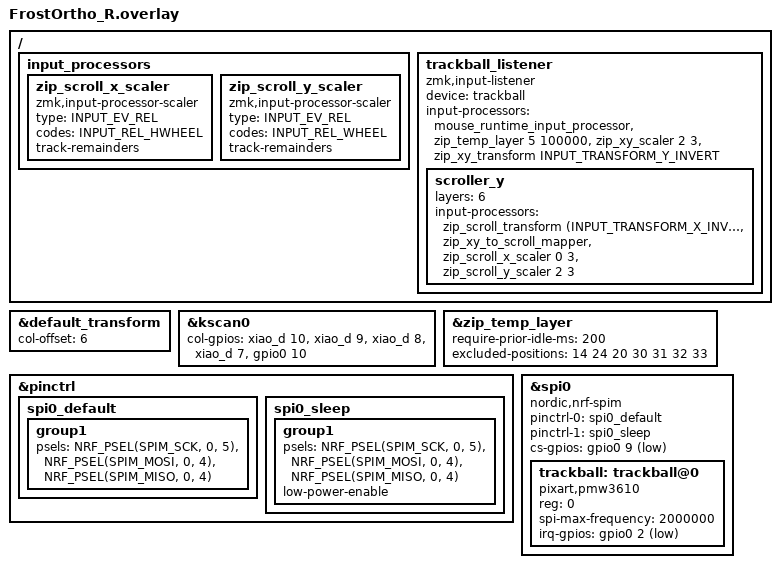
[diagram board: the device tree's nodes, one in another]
#include "FrostOrtho.dtsi"
#include <input/processors.dtsi>
#include <dt-bindings/zmk/input_transform.h>
#include <zephyr/dt-bindings/input/input-event-codes.h>
#include <input/processors/runtime-input-processor.dtsi>
#include <behaviors/battery_history_request.dtsi>

&default_transform {
    col-offset = <6>;
};

&kscan0 {
    col-gpios
        = <&xiao_d 10 GPIO_ACTIVE_HIGH>
        , <&xiao_d 9 GPIO_ACTIVE_HIGH> 
        , <&xiao_d 8 GPIO_ACTIVE_HIGH> 
        , <&xiao_d 7 GPIO_ACTIVE_HIGH> 
        , <&gpio0 10 GPIO_ACTIVE_HIGH>
        ;
};

// 自動滑鼠層不退出的按鍵（moNa2式：左手點擊）
&zip_temp_layer {
    require-prior-idle-ms = <200>;
    excluded-positions = <
        14 // G 左鍵 (MB1)
        24 // B 右鍵 (MB2)
        20 // Z 左Shift (mod-tap)
        30 // 左Shift (拇指)
        31 // 左Ctrl (拇指)
        32 // 左Alt / Layer 3 (拇指)
        33 // 左Command (拇指)
    >;
};

/ {
    input_processors {
        zip_scroll_x_scaler: zip_scroll_x_scaler {
            compatible = "zmk,input-processor-scaler";
            #input-processor-cells = <2>;
            type = <INPUT_EV_REL>;
            codes = <INPUT_REL_HWHEEL>;
            track-remainders;
        };
        zip_scroll_y_scaler: zip_scroll_y_scaler {
            compatible = "zmk,input-processor-scaler";
            #input-processor-cells = <2>;
            type = <INPUT_EV_REL>;
            codes = <INPUT_REL_WHEEL>;
            track-remainders;
        };
    };
};

/ {
    trackball_listener: trackball_listener {
        status = "okay";
        compatible = "zmk,input-listener";
        device = <&trackball>;

        // input-processors = <&mouse_runtime_input_processor>;
        input-processors = <
            &mouse_runtime_input_processor
            &zip_temp_layer 5 100000 // 自動滑鼠層（MOUSE=5），逾時時間
            &zip_xy_scaler 2 3 // 游標移動量 2/3 倍
            &zip_xy_transform INPUT_TRANSFORM_Y_INVERT // 游標移動方向校正
        >;
    };
};

&trackball_listener {
    scroller_y {
        layers = <6>; // 捲動層（SCROLL=6）
        input-processors = <
            // &scroll_runtime_input_processor
            &zip_scroll_transform (INPUT_TRANSFORM_X_INVERT) // 捲動方向校正
            &zip_xy_to_scroll_mapper
            &zip_scroll_x_scaler 0 3 // X軸捲動量 0/3 倍
            &zip_scroll_y_scaler 2 3 // Y軸捲動量 2/3 倍
        >;
    };
    // 已移除水平捲動（moNa2 風格：僅縱向捲動）
};

&pinctrl {
    spi0_default: spi0_default {
        group1 {
            psels = <NRF_PSEL(SPIM_SCK, 0, 5)>,
                <NRF_PSEL(SPIM_MOSI, 0, 4)>,
                <NRF_PSEL(SPIM_MISO, 0, 4)>;
        };
    };

    spi0_sleep: spi0_sleep {
        group1 {
            psels = <NRF_PSEL(SPIM_SCK, 0, 5)>,
                <NRF_PSEL(SPIM_MOSI, 0, 4)>,
                <NRF_PSEL(SPIM_MISO, 0, 4)>;
            low-power-enable;
        };
    };
};

&spi0 {
    status = "okay";
    compatible = "nordic,nrf-spim";
    pinctrl-0 = <&spi0_default>;
    pinctrl-1 = <&spi0_sleep>;
    pinctrl-names = "default", "sleep";
    cs-gpios = <&gpio0 9 GPIO_ACTIVE_LOW>;

    trackball: trackball@0 {
        status = "okay";
        compatible = "pixart,pmw3610";
        reg = <0>;
        spi-max-frequency = <2000000>;
        irq-gpios = <&gpio0 2 (GPIO_ACTIVE_LOW | GPIO_PULL_UP)>;
        // automouse-layer = <5>;  // MOUSE
        // scroll-layers = <6>;   // SCROLL
    };
};


